# wl_phy_rxt_secure register map
Vendor: Texas Instruments
Registers are 32-bit, access per field, no defined reset value unless marked. A register's access mark holds for its fields unless they carry their own. Offsets are as the file gives them; [hi:lo] are bit positions; {n}, {i} and the like mark numbered series; <NAME> marks a mode.

## wl_phy_rxt_secure (part 2 of 2)
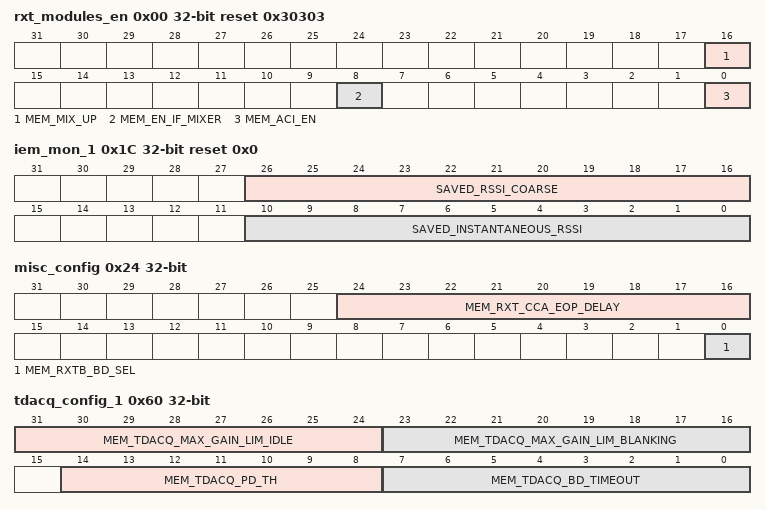
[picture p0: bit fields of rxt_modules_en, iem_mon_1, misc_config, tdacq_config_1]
0x00 rxt_modules_en reset 0x30303
  [16] MEM_MIX_UP rw, [8] MEM_EN_IF_MIXER rw, [0] MEM_ACI_EN rw
0x1C iem_mon_1 ro reset 0x0
  [26:16] SAVED_RSSI_COARSE, [10:0] SAVED_INSTANTANEOUS_RSSI
0x24 misc_config
  [24:16] MEM_RXT_CCA_EOP_DELAY rw, [0] MEM_RXTB_BD_SEL rw
0x5C tdram_config_1 reset 0x208
  [5:0] MEM_TDRAM_BD_OFFSET rw
0x60 tdacq_config_1
  [31:24] MEM_TDACQ_MAX_GAIN_LIM_IDLE rw, [23:16] MEM_TDACQ_MAX_GAIN_LIM_BLANKING rw, [14:8] MEM_TDACQ_PD_TH rw, [7:0] MEM_TDACQ_BD_TIMEOUT rw
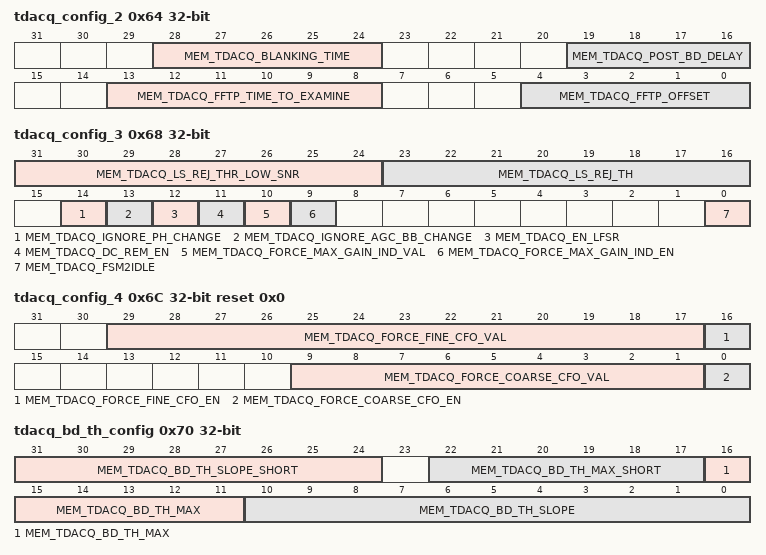
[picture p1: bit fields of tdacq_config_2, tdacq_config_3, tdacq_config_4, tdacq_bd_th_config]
0x64 tdacq_config_2
  [28:24] MEM_TDACQ_BLANKING_TIME rw, [19:16] MEM_TDACQ_POST_BD_DELAY rw, [13:8] MEM_TDACQ_FFTP_TIME_TO_EXAMINE rw, [4:0] MEM_TDACQ_FFTP_OFFSET rw
0x68 tdacq_config_3
  [31:24] MEM_TDACQ_LS_REJ_THR_LOW_SNR rw, [23:16] MEM_TDACQ_LS_REJ_TH rw, [14] MEM_TDACQ_IGNORE_PH_CHANGE rw, [13] MEM_TDACQ_IGNORE_AGC_BB_CHANGE rw, [12] MEM_TDACQ_EN_LFSR rw, [11] MEM_TDACQ_DC_REM_EN rw, [10] MEM_TDACQ_FORCE_MAX_GAIN_IND_VAL rw, [9] MEM_TDACQ_FORCE_MAX_GAIN_IND_EN rw, [0] MEM_TDACQ_FSM2IDLE rw
0x6C tdacq_config_4 reset 0x0
  [29:17] MEM_TDACQ_FORCE_FINE_CFO_VAL rw, [16] MEM_TDACQ_FORCE_FINE_CFO_EN rw, [9:1] MEM_TDACQ_FORCE_COARSE_CFO_VAL rw, [0] MEM_TDACQ_FORCE_COARSE_CFO_EN rw
0x70 tdacq_bd_th_config
  [31:24] MEM_TDACQ_BD_TH_SLOPE_SHORT rw, [22:17] MEM_TDACQ_BD_TH_MAX_SHORT rw, [16:11] MEM_TDACQ_BD_TH_MAX rw, [10:0] MEM_TDACQ_BD_TH_SLOPE rw
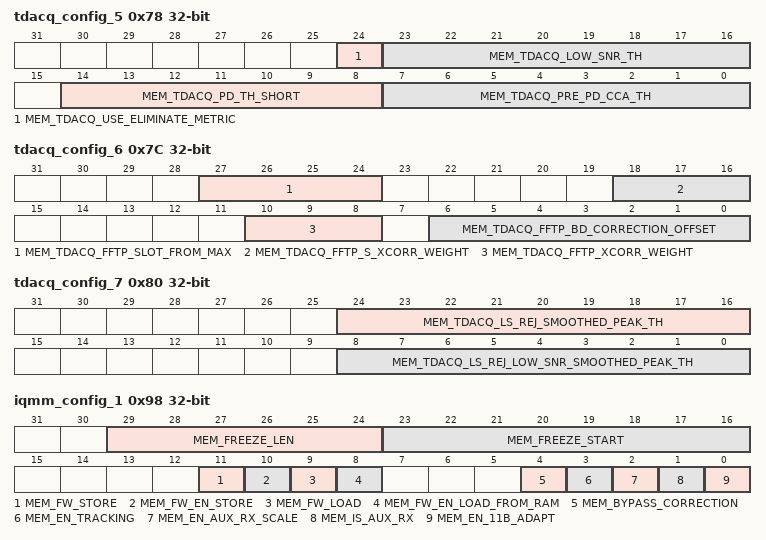
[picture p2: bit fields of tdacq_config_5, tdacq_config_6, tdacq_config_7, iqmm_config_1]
0x78 tdacq_config_5
  [24] MEM_TDACQ_USE_ELIMINATE_METRIC rw — For the short metric, weather to use the spur cancelation metric or not.
  [23:16] MEM_TDACQ_LOW_SNR_TH rw — For the LS Reject mechanism. Threshold for high/low snr. If total gain is higher than threshold, Ls Rej Low SNR thresholds are used
  [14:8] MEM_TDACQ_PD_TH_SHORT rw — Threshold for the packet detection, short metric. Raise threshold for less FA on the expense of detection probability.
  [7:0] MEM_TDACQ_PRE_PD_CCA_TH rw — Threshold for the pre PD CCA. Raise threshold for less FA on the expense of detection probability.
0x7C tdacq_config_6
  [27:24] MEM_TDACQ_FFTP_SLOT_FROM_MAX rw — The max fftp delay allowed after max values of the metrics
  [18:16] MEM_TDACQ_FFTP_S_XCORR_WEIGHT rw — For the fftp metric, multiply the difference of the SmoothedXcorr value from its max*0.625. The weight is relative to FftpXcorrWeight.
  [10:8] MEM_TDACQ_FFTP_XCORR_WEIGHT rw — For the fftp metric, multiply the difference of the Xcorr value from its max*0.625. The weight is relative to FftpSXcorrWeight.
  [6:0] MEM_TDACQ_FFTP_BD_CORRECTION_OFFSET rw — The offset we add to Equals fftp_correlation_series_start_point_in_40_MHz_clk - 2*PostBdDelay + fine tuning.
0x80 tdacq_config_7
  [24:16] MEM_TDACQ_LS_REJ_SMOOTHED_PEAK_TH rw, [8:0] MEM_TDACQ_LS_REJ_LOW_SNR_SMOOTHED_PEAK_TH rw
0x84 tdacq_config_8 reset 0x1F4FA
  [8:0] MEM_TDACQ_LS_REJ_PEAK_TH rw
0x88 tdacq_fftp_correlation_series_1 rw reset 0xAC204C53
  [31:0] MEM_TDACQ_FFTP_CORRELATION_SERIES_PH0_15
0x8C tdacq_fftp_correlation_series_2 rw reset 0x42FA156F
  [31:0] MEM_TDACQ_FFTP_CORRELATION_SERIES_PH16_31
0x90 tdacq_fftp_correlation_series_3 rw reset 0xDF141AAD
  [31:0] MEM_TDACQ_FFTP_CORRELATION_SERIES_PH32_47
0x94 tdacq_fftp_correlation_series_4 rw reset 0xC7B0EB3B
  [31:0] MEM_TDACQ_FFTP_CORRELATION_SERIES_PH48_63
0x98 iqmm_config_1
  [29:24] MEM_FREEZE_LEN rw — Freeze length in (x16) cycles
  [23:16] MEM_FREEZE_START rw — Freeze start time. The number of (x16) cycles between packet adaptation start and freeze start. 'all 1' means no freeze
  [11] MEM_FW_STORE rw
  [10] MEM_FW_EN_STORE rw
  [9] MEM_FW_LOAD rw
  [8] MEM_FW_EN_LOAD_FROM_RAM rw
  [4] MEM_BYPASS_CORRECTION rw
  [3] MEM_EN_TRACKING rw
  [2] MEM_EN_AUX_RX_SCALE rw
  [1] MEM_IS_AUX_RX rw
  [0] MEM_EN_11B_ADAPT rw
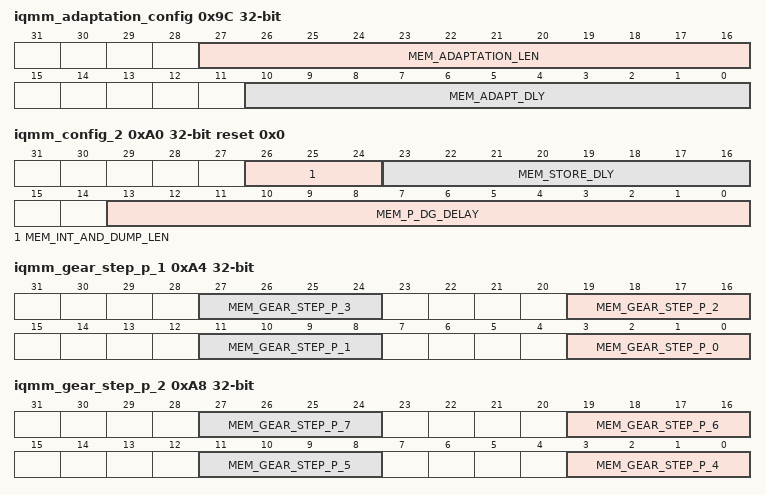
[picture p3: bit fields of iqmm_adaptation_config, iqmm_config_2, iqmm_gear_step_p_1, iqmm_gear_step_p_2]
0x9C iqmm_adaptation_config
  [27:16] MEM_ADAPTATION_LEN rw — Adaptation length of the acquisition stage (x128) cycles.
  [10:0] MEM_ADAPT_DLY rw — Delay in cycles between the adaptation start command (AgcLock or Fwstart) and the actual adaptation start.
0xA0 iqmm_config_2 reset 0x0
  [26:24] MEM_INT_AND_DUMP_LEN rw — Integrate and dump length in powers of 2. The register value represents the log2 of the length.Supports lengths of 1,16,64 and 128
  [23:16] MEM_STORE_DLY rw — Delay in cycles between the adaptation stop (end of packet or end of acquisition) and the actual P,dG and AdaptCount store to RAM
  [13:0] MEM_P_DG_DELAY rw — Delay in (x32) cycles between the Global adaptation start (where P starts) and the dG adaptation start.
0xA4 iqmm_gear_step_p_1
  [8n+3:8n] MEM_GEAR_STEP_P_{n} rw (n=0..3) — P step size function values - in number of shift left operations. Bus span is 0 to 15, it represents gears 2 to 17
0xA8 iqmm_gear_step_p_2
  [8n-29:8n-32] MEM_GEAR_STEP_P_{n} rw (n=4..7) — P step size function values - in number of shift left operations. Bus span is 0 to 15, it represents gears 2 to 17
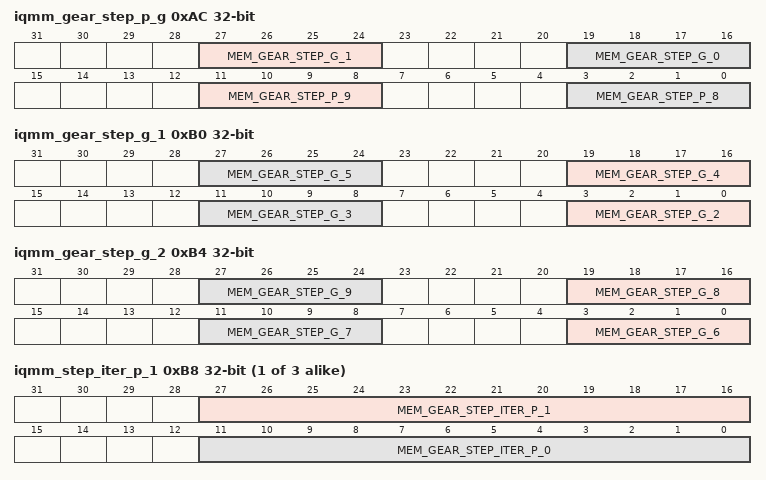
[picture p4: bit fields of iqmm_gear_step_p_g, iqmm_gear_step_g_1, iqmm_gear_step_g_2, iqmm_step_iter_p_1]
0xAC iqmm_gear_step_p_g
  [27:24] MEM_GEAR_STEP_G_1 rw — dG step size function values - in number of shift left operations. Bus span is 0 to 15, it represents gears 2 to 17
  [19:16] MEM_GEAR_STEP_G_0 rw — dG step size function values - in number of shift left operations. Bus span is 0 to 15, it represents gears 2 to 17
  [11:8] MEM_GEAR_STEP_P_9 rw — P step size function values - in number of shift left operations. Bus span is 0 to 15, it represents gears 2 to 17
  [3:0] MEM_GEAR_STEP_P_8 rw — P step size function values - in number of shift left operations. Bus span is 0 to 15, it represents gears 2 to 17
0xB0 iqmm_gear_step_g_1
  [8n-13:8n-16] MEM_GEAR_STEP_G_{n} rw (n=2..5) — dG step size function values - in number of shift left operations. Bus span is 0 to 15, it represents gears 2 to 17
0xB4 iqmm_gear_step_g_2
  [8n-45:8n-48] MEM_GEAR_STEP_G_{n} rw (n=6..9) — dG step size function values - in number of shift left operations. Bus span is 0 to 15, it represents gears 2 to 17
{0xB4+4i} iqmm_step_iter_p_{i} (i=1..3)
  [27:16] MEM_GEAR_STEP_ITER_P_{2i-1} rw — P step size function time stamp values - in resolution of (x128) cycles.
  [11:0] MEM_GEAR_STEP_ITER_P_{2i-2} rw — P step size function time stamp values - in resolution of (x128) cycles.
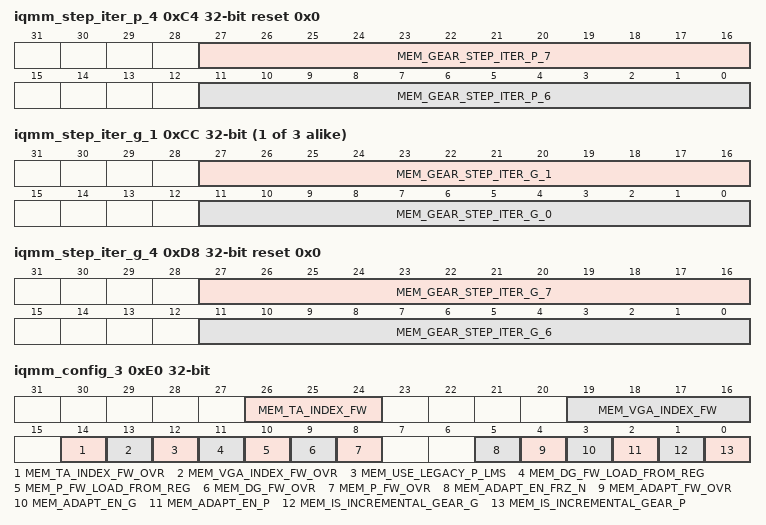
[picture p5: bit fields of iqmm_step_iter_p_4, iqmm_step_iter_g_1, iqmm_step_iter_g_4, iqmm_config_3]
0xC4 iqmm_step_iter_p_4 reset 0x0
  [27:16] MEM_GEAR_STEP_ITER_P_7 rw — P step size function time stamp values - in resolution of (x128) cycles.
  [11:0] MEM_GEAR_STEP_ITER_P_6 rw — P step size function time stamp values - in resolution of (x128) cycles.
0xC8 iqmm_step_iter_p_5 reset 0x0
  [11:0] MEM_GEAR_STEP_ITER_P_8 rw — P step size function time stamp values - in resolution of (x128) cycles.
{0xC8+4i} iqmm_step_iter_g_{i} (i=1..3)
  [27:16] MEM_GEAR_STEP_ITER_G_{2i-1} rw — dG step size function time stamp values - in resolution of (x128) cycles.
  [11:0] MEM_GEAR_STEP_ITER_G_{2i-2} rw — dG step size function time stamp values - in resolution of (x128) cycles.
0xD8 iqmm_step_iter_g_4 reset 0x0
  [27:16] MEM_GEAR_STEP_ITER_G_7 rw — dG step size function time stamp values - in resolution of (x128) cycles.
  [11:0] MEM_GEAR_STEP_ITER_G_6 rw — dG step size function time stamp values - in resolution of (x128) cycles.
0xDC iqmm_step_iter_g_5 reset 0x0
  [11:0] MEM_GEAR_STEP_ITER_G_8 rw — dG step size function time stamp values - in resolution of (x128) cycles.
0xE0 iqmm_config_3
  [26:24] MEM_TA_INDEX_FW rw — Ta Index value from FW [0..4]
  [19:16] MEM_VGA_INDEX_FW rw — Vga Index value from FW [0..8]
  [14] MEM_TA_INDEX_FW_OVR rw
  [13] MEM_VGA_INDEX_FW_OVR rw
  [12] MEM_USE_LEGACY_P_LMS rw
  [11] MEM_DG_FW_LOAD_FROM_REG rw
  [10] MEM_P_FW_LOAD_FROM_REG rw
  [9] MEM_DG_FW_OVR rw
  [8] MEM_P_FW_OVR rw
  [5] MEM_ADAPT_EN_FRZ_N rw
  [4] MEM_ADAPT_FW_OVR rw
  [3] MEM_ADAPT_EN_G rw
  [2] MEM_ADAPT_EN_P rw
  [1] MEM_IS_INCREMENTAL_GEAR_G rw
  [0] MEM_IS_INCREMENTAL_GEAR_P rw
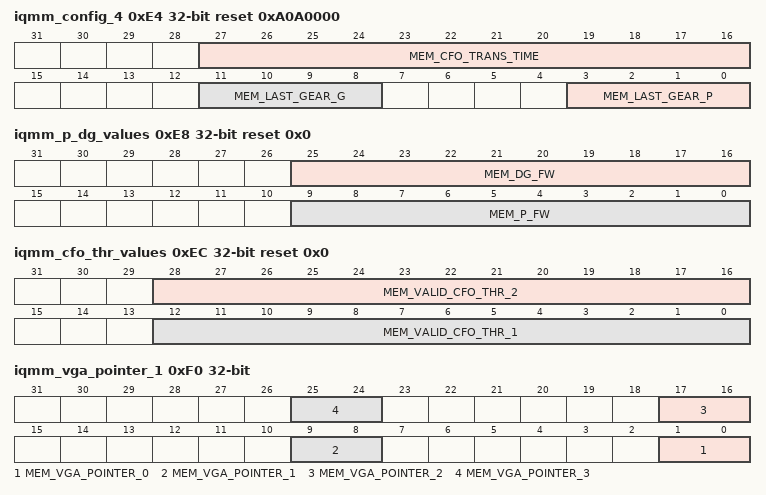
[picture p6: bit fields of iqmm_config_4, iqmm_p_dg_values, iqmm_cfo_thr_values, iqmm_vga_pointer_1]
0xE4 iqmm_config_4 reset 0xA0A0000 (reset mask 0xFFF0000)
  [27:16] MEM_CFO_TRANS_TIME rw — The time in x128 samples to switch between ValidCfoThr1 and ValidCfoThr2
  [11:8] MEM_LAST_GEAR_G rw — Last G Gear limit
  [3:0] MEM_LAST_GEAR_P rw — Last P Gear limit
0xE8 iqmm_p_dg_values reset 0x0
  [25:16] MEM_DG_FW rw — dG value from FW used for FW override or to load into the LMS loop
  [9:0] MEM_P_FW rw — P value from FW used for FW override or to load into the LMS loop
0xEC iqmm_cfo_thr_values reset 0x0
  [28:16] MEM_VALID_CFO_THR_2 rw — Second CFO Threshold to validate the packet adaptation cycle. If the CFO is lower than the threshold the packet adaptation result will not be written to the RAM This threshold is used when AdaptCount > CfoThrTransTime.
  [12:0] MEM_VALID_CFO_THR_1 rw — First CFO Threshold to validate the packet adaptation cycle. If the CFO is lower than the threshold the packet adaptation result will not be written to the RAM. This threshold is used when AdaptCount <= CfoThrTransTime
0xF0 iqmm_vga_pointer_1
  [8n+1:8n] MEM_VGA_POINTER_{n} rw (n=0..3)
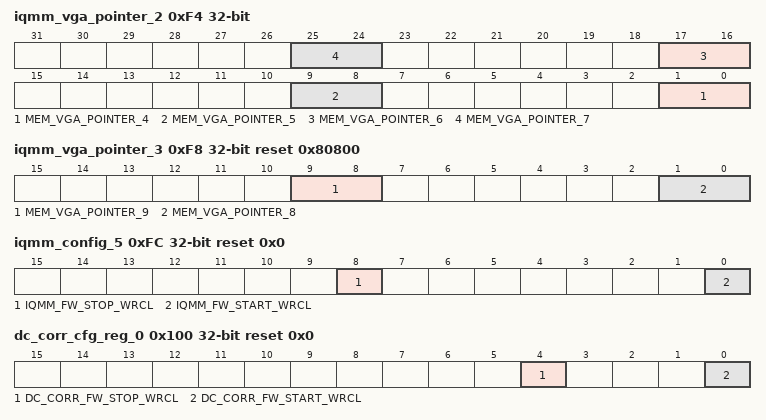
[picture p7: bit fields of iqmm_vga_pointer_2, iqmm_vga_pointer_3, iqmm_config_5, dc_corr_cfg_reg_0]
0xF4 iqmm_vga_pointer_2
  [8n-31:8n-32] MEM_VGA_POINTER_{n} rw (n=4..7)
0xF8 iqmm_vga_pointer_3 reset 0x80800 (reset mask 0xFFFFFC00)
  [9:8] MEM_VGA_POINTER_9 rw, [1:0] MEM_VGA_POINTER_8 rw
0xFC iqmm_config_5 reset 0x0
  [8] IQMM_FW_STOP_WRCL wo, [0] IQMM_FW_START_WRCL wo
0x100 dc_corr_cfg_reg_0 reset 0x0 — FW Overwrite configuration register
  [4] DC_CORR_FW_STOP_WRCL wo — Stop the DC correction - triggered from FW. Self Clear <1.0u>
  [0] DC_CORR_FW_START_WRCL wo — Start new DC correction - triggered from FW. Self Clear <1.0u>
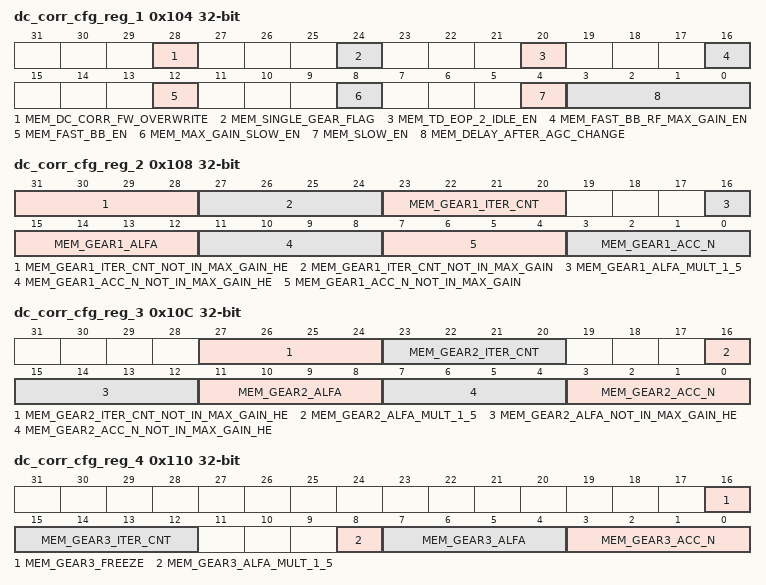
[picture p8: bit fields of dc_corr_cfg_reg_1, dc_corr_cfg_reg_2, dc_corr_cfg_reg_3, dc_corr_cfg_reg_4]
0x104 dc_corr_cfg_reg_1 — Enable configuration register
  [28] MEM_DC_CORR_FW_OVERWRITE rw — If set, only the FW controls start/stop and not inner signals such as Abort/EOP/StartTd <1.0u>
  [24] MEM_SINGLE_GEAR_FLAG rw — If set, only the first gear is used <1.0u>
  [20] MEM_TD_EOP_2_IDLE_EN rw — If enabled, EOP packet pulse resets the DC correction into idle. <1.0u>
  [16] MEM_FAST_BB_RF_MAX_GAIN_EN rw — If set, BB(VGA) change will cause scaling of the DC correction value (according to the VGA change) without reset of the DC module only when RF is in max gain (LNA+TA). <1.0u>
  [12] MEM_FAST_BB_EN rw — If set, BB(VGA) change will cause scaling of the DC correction value (according to the VGA change) without reset of the DC module (DC is assumed constant during BB change). <1.0u>
  [8] MEM_MAX_GAIN_SLOW_EN rw — When enabled, enables switching from Gear 3 STATE into Slow1 STATE only if AGC is in max gain. <1.0u>
  [4] MEM_SLOW_EN rw — When enabled always switch from Gear 3 STATE into Slow1 STATE <1.0u>
  [3:0] MEM_DELAY_AFTER_AGC_CHANGE rw — Delay value after agc change (RfChange|BBChange) <4.0u>
0x108 dc_corr_cfg_reg_2 — Gear 1 configuation register
  [31:28] MEM_GEAR1_ITER_CNT_NOT_IN_MAX_GAIN_HE rw — Number of clocks to stay at Gear1. This register is used after AGC change in the middle of the He-STF to prevent DC change after possible long ?Gear1AccN?(as is the default value) which might interfere with the He-LTF estimation. We want to ensure Gear1AccNNotInMaxGainHe is used only once(equals Gear1AccNNotInMaxGainHe) <4.0u>
  [27:24] MEM_GEAR1_ITER_CNT_NOT_IN_MAX_GAIN rw — Number of clocks to stay at Gear1. Number of clocks to stay at Gear1. value is This register is used after AGC change in the middle of the legacy preamble to prevent first DC change after possible long ?Gear1AccN?(as is the default value) which might interfere with the placement algorithm. We allow different register for that mode. We want to ensure Gear1AccNNotInMaxGain is used only once(equals Gear1AccNNotInMaxGain) <4.0u>
  [23:20] MEM_GEAR1_ITER_CNT rw — Number of clocks to stay at Gear1. <4.0u>
  [16] MEM_GEAR1_ALFA_MULT_1_5 rw — 1.5 multiplier enable for Alfa of Gear 1 <1.0u>
  [15:12] MEM_GEAR1_ALFA rw — Alfa value for Gear1. <4.0u>
  [11:8] MEM_GEAR1_ACC_N_NOT_IN_MAX_GAIN_HE rw — Accumulator duration (40Mhz cycles) for Gear1 when not in max gain. This register is used after AGC change in the middle of the He-STF to prevent DC change after possible long ?Gear1AccN?(as is the default value) which might interfere with the He-LTF estimation. <4.0u>
  [7:4] MEM_GEAR1_ACC_N_NOT_IN_MAX_GAIN rw — Accumulator duration (40Mhz cycles) for Gear1 when not in max gain. This register is used after AGC change in the middle of the legacy preamble to prevent first DC change after possible long ?Gear1AccN?(as is the default value) which might interfere with the placement algorithm. We allow different register for that mode. <4.0u>
  [3:0] MEM_GEAR1_ACC_N rw — Accumulator duration (40Mhz cycles) for Gear1. <4.0u>
0x10C dc_corr_cfg_reg_3 — Gear 2 configuration register
  [27:24] MEM_GEAR2_ITER_CNT_NOT_IN_MAX_GAIN_HE rw — Number of clocks to stay at Gear2. See explanation in Gear2AccnNotInMaxGainHe <4.0u>
  [23:20] MEM_GEAR2_ITER_CNT rw — Number of clocks to stay at Gear2. <4.0u>
  [16] MEM_GEAR2_ALFA_MULT_1_5 rw — 1.5 multiplier enable for Alfa of Gear 2 <1.0u>
  [15:12] MEM_GEAR2_ALFA_NOT_IN_MAX_GAIN_HE rw — Alfa value for Gear2. See explanation in Gear2AccnNotInMaxGainHe <4.0u>
  [11:8] MEM_GEAR2_ALFA rw — Alfa value for Gear2. <4.0u>
  [7:4] MEM_GEAR2_ACC_N_NOT_IN_MAX_GAIN_HE rw — Accumulator duration (40Mhz cycles) for Gear2. Accumulator duration (40Mhz cycles) for Gear2. Value is This register is used after AGC change in the middle of the He-STF to prevent DC change after possible long ?Gear1AccN?(as is the default value) which might interfere with the He-LTF estimation. After first averaging with duration 1.6usec (Gear1AccNNotInMaxGainHe) we want 0.8 usec more averaging with gear2. <4.0u>
  [3:0] MEM_GEAR2_ACC_N rw — Accumulator duration (40Mhz cycles) for Gear2. <4.0u>
0x110 dc_corr_cfg_reg_4 — Gear 3 configuration register
  [16] MEM_GEAR3_FREEZE rw — Freeze adaptation for gear3 <1.0u>
  [15:12] MEM_GEAR3_ITER_CNT rw — Number of clocks to stay at Gear3. <4.0u>
  [8] MEM_GEAR3_ALFA_MULT_1_5 rw — 1.5 multiplier enable for Alfa of Gear 3 <1.0u>
  [7:4] MEM_GEAR3_ALFA rw — Alfa value for Gear3. <4.0u>
  [3:0] MEM_GEAR3_ACC_N rw — Accumulator duration (40Mhz cycles) for Gear3. <4.0>
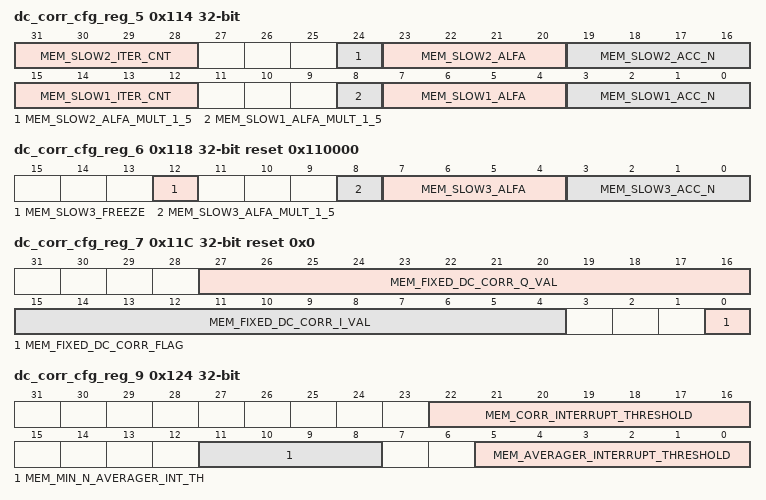
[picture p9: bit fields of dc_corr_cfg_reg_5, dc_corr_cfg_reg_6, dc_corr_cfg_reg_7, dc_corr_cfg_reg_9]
0x114 dc_corr_cfg_reg_5 — Slow 1 and Slow 2 configuration register
  [31:28] MEM_SLOW2_ITER_CNT rw — Number of clocks to stay at Slow2. <4.0u>
  [24] MEM_SLOW2_ALFA_MULT_1_5 rw — 1.5 multiplier enable for Alfa of Slow 2 <1.0u>
  [23:20] MEM_SLOW2_ALFA rw — Alfa value for Slow2. <4.0u>
  [19:16] MEM_SLOW2_ACC_N rw — Accumulator duration (40Mhz cycles) for Slow2. <4.0u>
  [15:12] MEM_SLOW1_ITER_CNT rw — Number of clocks to stay at Slow1. <4.0u>
  [8] MEM_SLOW1_ALFA_MULT_1_5 rw — 1.5 multiplier enable for Alfa of Slow 1 <1.0u>
  [7:4] MEM_SLOW1_ALFA rw — Alfa value for Slow1. <4.0u>
  [3:0] MEM_SLOW1_ACC_N rw — Accumulator duration (40Mhz cycles) for Slow1. <4.0u>
0x118 dc_corr_cfg_reg_6 reset 0x110000 (reset mask 0xFFFFE000) — Slow 3 configuration register
  [12] MEM_SLOW3_FREEZE rw — Freeze adaptation for Slow3 <1.0u>
  [8] MEM_SLOW3_ALFA_MULT_1_5 rw — 1.5 multiplier enable for Alfa of Slow 3 <4.0u>
  [7:4] MEM_SLOW3_ALFA rw — Alfa value for Slow3. <4.0u>
  [3:0] MEM_SLOW3_ACC_N rw — Accumulator duration (40Mhz cycles) for Slow3. <4.0u>
0x11C dc_corr_cfg_reg_7 reset 0x0 — Fixed DC correction configuration register
  [27:16] MEM_FIXED_DC_CORR_Q_VAL rw — Imaginary part of external forced DC correction <1.11s>
  [15:4] MEM_FIXED_DC_CORR_I_VAL rw — Real part of external forced DC correction <1.11s>
  [0] MEM_FIXED_DC_CORR_FLAG rw — If set, overwrite DC correction by FixedDcCorrectionVal_XX <1.0u>
0x124 dc_corr_cfg_reg_9 — Interrrupt thresholds configuration register
  [22:16] MEM_CORR_INTERRUPT_THRESHOLD rw — If the amplitude (real or imag) of the Correction exceeds register CorrInterruptThreshold, BigCorrInt is set high. <0.7u>
  [11:8] MEM_MIN_N_AVERAGER_INT_TH rw — If the current gear?s AccN equals/greater than MinNAveragerIntTh then CorrInterrupt is enabled. <0.4u>
  [5:0] MEM_AVERAGER_INTERRUPT_THRESHOLD rw — If the amplitude (real or imag) of the averager exceeds register AvergarerInterruptThreshold, BigAveragerInt is set high. <0.6u>
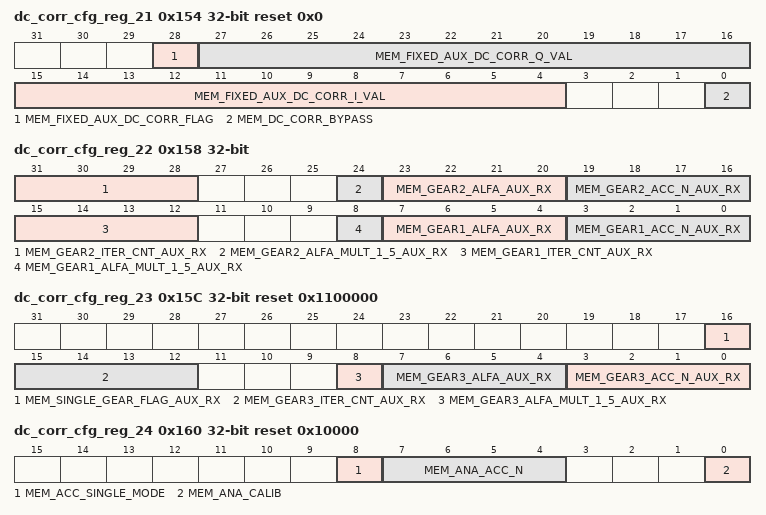
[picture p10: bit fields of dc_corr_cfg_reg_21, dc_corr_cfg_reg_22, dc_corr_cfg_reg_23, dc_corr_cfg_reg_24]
0x154 dc_corr_cfg_reg_21 reset 0x0 — DC Correction bypass configuration register
  [28] MEM_FIXED_AUX_DC_CORR_FLAG rw — If set, overwrite DC correction by FixedAuxRxDcCorrectionVal_XX when in aux rx mode (Tx calibration mode). <1.0u>
  [27:16] MEM_FIXED_AUX_DC_CORR_Q_VAL rw — Imaginary part of external forced DC correction when in aux rx (Tx calibration mode). <1.11s>
  [15:4] MEM_FIXED_AUX_DC_CORR_I_VAL rw — Real part of external forced DC correction when in aux rx mode (Tx calibration mode). <1.11s>
  [0] MEM_DC_CORR_BYPASS rw — If set, the DC correction is bypassed. <1.0u>
0x158 dc_corr_cfg_reg_22 — Gear 1 and Gear 2 Aux RX configuration register
  [31:28] MEM_GEAR2_ITER_CNT_AUX_RX rw — Number of clocks to stay at Gear2. <4.0u>
  [24] MEM_GEAR2_ALFA_MULT_1_5_AUX_RX rw — 1.5 multiplier enable for Alfa of Gear 2 <1.0u>
  [23:20] MEM_GEAR2_ALFA_AUX_RX rw — Alfa value for Gear2. <4.0u>
  [19:16] MEM_GEAR2_ACC_N_AUX_RX rw — Accumulator duration (40Mhz cycles) for Gear2. <4.0u>
  [15:12] MEM_GEAR1_ITER_CNT_AUX_RX rw — Number of clocks to stay at Gear1. <4.0u>
  [8] MEM_GEAR1_ALFA_MULT_1_5_AUX_RX rw — 1.5 multiplier enable for Alfa of Gear 1. <4.0u>
  [7:4] MEM_GEAR1_ALFA_AUX_RX rw — Alfa value for Gear1. <4.0u>
  [3:0] MEM_GEAR1_ACC_N_AUX_RX rw — Accumulator duration (40Mhz cycles) for Gear1. <4.0u>
0x15C dc_corr_cfg_reg_23 reset 0x1100000 (reset mask 0xFFFE0000) — Gear 3 and Signle gear Aux RX configuration register
  [16] MEM_SINGLE_GEAR_FLAG_AUX_RX rw — If set, only the first gear is used when in IsAuxRxMode <1.0u>
  [15:12] MEM_GEAR3_ITER_CNT_AUX_RX rw — Number of clocks to stay at Gear3. <4.0u>
  [8] MEM_GEAR3_ALFA_MULT_1_5_AUX_RX rw — 1.5 multiplier enable for Alfa of Gear 3 <1.0u>
  [7:4] MEM_GEAR3_ALFA_AUX_RX rw — Alfa value for Gear3. <4.0u>
  [3:0] MEM_GEAR3_ACC_N_AUX_RX rw — Accumulator duration (40Mhz cycles) for Gear3. <4.0>
0x160 dc_corr_cfg_reg_24 reset 0x10000 (reset mask 0xFFFFFE00) — Analog calibration configuration register
  [8] MEM_ACC_SINGLE_MODE rw — If set, the accumulator accumulates and dumps only one time (into Averager status register) after SingleMode is set high. The averaging duration is based on its current AccN value. In order to get new value for Averager status register, SingleMode register has to be reset and set. Important note: This register doesn?t change any other module functionality (The gears are progressing/DC correction is active, etc.). <1.0u>
  [7:4] MEM_ANA_ACC_N rw — Accumulator duration (40Mhz cycles) irrespective of the gear when AnalogCalib is set high. <4.0u>
  [0] MEM_ANA_CALIB rw — If set, the accumulator accumulates and dumps 2^ AccNAnalogCalib samples irrespective of the gear. Important note: This register doesn?t change any other module functionality (The gears are progressing/DC correction is active, etc.). <1.0u>
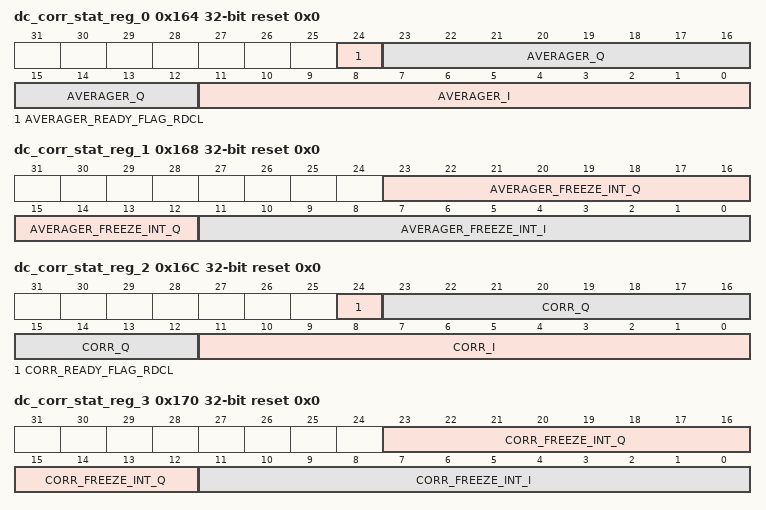
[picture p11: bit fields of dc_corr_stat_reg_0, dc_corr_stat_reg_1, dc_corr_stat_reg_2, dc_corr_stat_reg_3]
0x164 dc_corr_stat_reg_0 ro reset 0x0 — Averager status register
  [24] AVERAGER_READY_FLAG_RDCL — Set to high every update of Averager value. <1.0u>
  [23:12] AVERAGER_Q — The result of averaging imag branch GearXXAccN/ AccNAnalogCalib samples. This result is updated only once after ?SingleMode? register is set high. <1.11s>
  [11:0] AVERAGER_I — The result of averaging real branch GearXXAccN/ AccNAnalogCalib samples. This result is updated only once after ?SingleMode? register is set high. <1.11s>
0x168 dc_corr_stat_reg_1 ro reset 0x0 — Averager freeze status register
  [23:12] AVERAGER_FREEZE_INT_Q — The value of the imag branch Averager when BigAveragerInt set high.This value is max hold and FW should reset it during read.Each I/Q is freezed separately. <1.11s>
  [11:0] AVERAGER_FREEZE_INT_I — The value of the real branch Averager when BigAveragerInt set high.This value is max hold and FW should reset it during read.Each I/Q is freezed separately. <1.11s>
0x16C dc_corr_stat_reg_2 ro reset 0x0 — Correction status register
  [24] CORR_READY_FLAG_RDCL — Set to high every update of Corr value.
  [23:12] CORR_Q — DC correction imag branch value to be applied to input. <1.11s>
  [11:0] CORR_I — DC correction real branch value to be applied to input. <1.11s>
0x170 dc_corr_stat_reg_3 ro reset 0x0 — Correction freeze status register
  [23:12] CORR_FREEZE_INT_Q — The value of the imag branch Corr when BigCorrInt set high.This value is max hold and FW should reset it during read. Each I/Q is freezed separately. <1.11s>
  [11:0] CORR_FREEZE_INT_I — The value of the real branch Corr when BigCorrInt set high.This value is max hold and FW should reset it during read. Each I/Q is freezed separately. <1.11s>
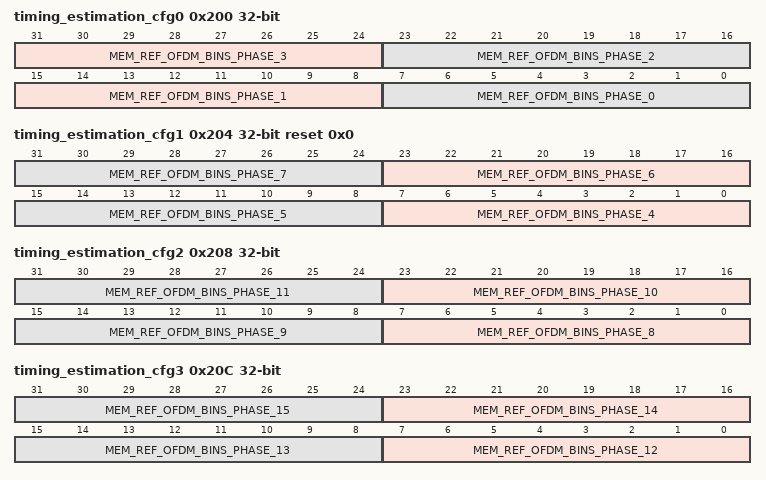
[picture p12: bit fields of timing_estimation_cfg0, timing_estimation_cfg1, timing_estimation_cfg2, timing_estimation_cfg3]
0x200 timing_estimation_cfg0 rw
  [31:24] MEM_REF_OFDM_BINS_PHASE_3 — Expected normalized phase which are matched to selected bins phase
  [23:16] MEM_REF_OFDM_BINS_PHASE_2 — Expected normalized phase which are matched to selected bins phase
  [15:8] MEM_REF_OFDM_BINS_PHASE_1 — Expected normalized phase which are matched to selected bins phase.
  [7:0] MEM_REF_OFDM_BINS_PHASE_0 — Expected normalized phase which are matched to selected bins phase.
0x204 timing_estimation_cfg1 rw reset 0x0
  [8n-25:8n-32] MEM_REF_OFDM_BINS_PHASE_{n} (n=4..7) — Expected normalized phase which are matched to selected bins phase
0x208 timing_estimation_cfg2 rw
  [8n-57:8n-64] MEM_REF_OFDM_BINS_PHASE_{n} (n=8..11) — Expected normalized phase which are matched to selected bins phase
0x20C timing_estimation_cfg3 rw
  [8n-89:8n-96] MEM_REF_OFDM_BINS_PHASE_{n} (n=12..15) — Expected normalized phase which are matched to selected bins phase
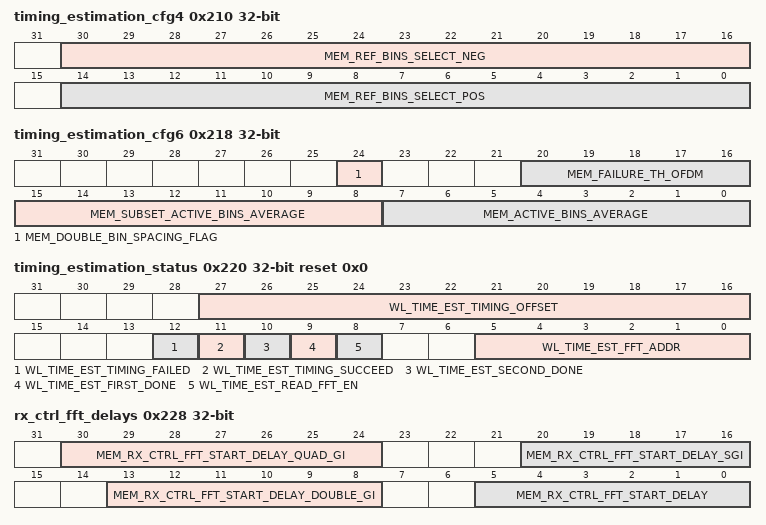
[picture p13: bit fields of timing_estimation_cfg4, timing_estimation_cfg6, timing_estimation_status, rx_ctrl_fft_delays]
0x210 timing_estimation_cfg4
  [30:16] MEM_REF_BINS_SELECT_NEG rw — Selection of active bins.
  [14:0] MEM_REF_BINS_SELECT_POS rw — Selection of active bins.
0x218 timing_estimation_cfg6
  [24] MEM_DOUBLE_BIN_SPACING_FLAG rw — If set, the active bins used for estimation will be taken from twice bin index as defined in Ref_ofdm_bins_select_XX.
  [20:16] MEM_FAILURE_TH_OFDM rw — This is the accumulated distance threshold between true and estimated phase. If accumulated distance exceeds Failure_th, then estimation failed.
  [15:8] MEM_SUBSET_ACTIVE_BINS_AVERAGE rw
  [7:0] MEM_ACTIVE_BINS_AVERAGE rw
0x21C timing_estimation_cfg7 reset 0x28341
  [8:0] MEM_INV_SCALING rw
0x220 timing_estimation_status ro reset 0x0
  [27:16] WL_TIME_EST_TIMING_OFFSET, [12] WL_TIME_EST_TIMING_FAILED, [11] WL_TIME_EST_TIMING_SUCCEED, [10] WL_TIME_EST_SECOND_DONE, [9] WL_TIME_EST_FIRST_DONE, [8] WL_TIME_EST_READ_FFT_EN, [5:0] WL_TIME_EST_FFT_ADDR
0x224 timing_estimation_status_2 ro reset 0x0
  [7:0] WL_TIME_EST_COMMON_PHASE
0x228 rx_ctrl_fft_delays
  [30:24] MEM_RX_CTRL_FFT_START_DELAY_QUAD_GI rw — Configurable delay to align the FftStart of the HE-LTF when GI=3.2usec according to the new Fft placement value.
  [20:16] MEM_RX_CTRL_FFT_START_DELAY_SGI rw — Configurable delay to align the FftStart of the HT/VHT-LTF in an SGI packet according to the new Fft placement value. FftStartDelaySgi = 16 + FftpSgi ? Fftp
  [13:8] MEM_RX_CTRL_FFT_START_DELAY_DOUBLE_GI rw — Configurable delay to align the FftStart of the HE-LTF when GI=1.6usec according to the new Fft placement value.
  [5:0] MEM_RX_CTRL_FFT_START_DELAY rw — Configurable delay for the first FftStart. Used as part of the total delay from BD to the first FftStart.
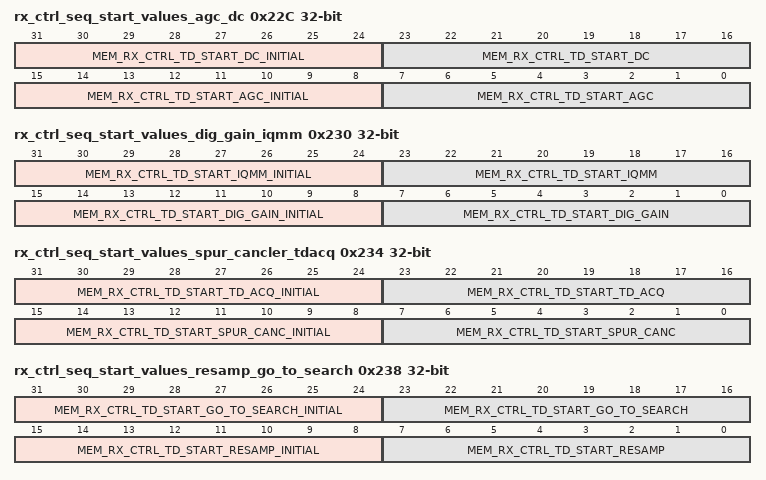
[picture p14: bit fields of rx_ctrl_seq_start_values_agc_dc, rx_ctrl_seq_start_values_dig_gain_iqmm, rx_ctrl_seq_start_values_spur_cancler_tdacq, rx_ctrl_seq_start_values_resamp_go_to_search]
0x22C rx_ctrl_seq_start_values_agc_dc rw
  [31:24] MEM_RX_CTRL_TD_START_DC_INITIAL — Dc cancellation start time for 1st packet sequence
  [23:16] MEM_RX_CTRL_TD_START_DC — Dc cancellation start time for 2nd sequence
  [15:8] MEM_RX_CTRL_TD_START_AGC_INITIAL — Agc start time for 1st packet sequence
  [7:0] MEM_RX_CTRL_TD_START_AGC — Agc start time for 2nd sequence
0x230 rx_ctrl_seq_start_values_dig_gain_iqmm rw
  [31:24] MEM_RX_CTRL_TD_START_IQMM_INITIAL — Iqmm start time for 1st packet sequence
  [23:16] MEM_RX_CTRL_TD_START_IQMM — Iqmm start time for 2nd sequence
  [15:8] MEM_RX_CTRL_TD_START_DIG_GAIN_INITIAL — Dig gain start time for 1st packet sequence
  [7:0] MEM_RX_CTRL_TD_START_DIG_GAIN — Dig gain start time for 2nd sequence
0x234 rx_ctrl_seq_start_values_spur_cancler_tdacq rw
  [31:24] MEM_RX_CTRL_TD_START_TD_ACQ_INITIAL — td_acq start time for 1st packet
  [23:16] MEM_RX_CTRL_TD_START_TD_ACQ — td_acq start time for 2nd sequence
  [15:8] MEM_RX_CTRL_TD_START_SPUR_CANC_INITIAL — spur canceler start time for 1st packet sequence
  [7:0] MEM_RX_CTRL_TD_START_SPUR_CANC — spur canceler start time for 2nd sequence
0x238 rx_ctrl_seq_start_values_resamp_go_to_search rw
  [31:24] MEM_RX_CTRL_TD_START_GO_TO_SEARCH_INITIAL — 2nd packet sequence done time
  [23:16] MEM_RX_CTRL_TD_START_GO_TO_SEARCH — 1st packet sequence done time
  [15:8] MEM_RX_CTRL_TD_START_RESAMP_INITIAL — Reset resampler time for 1st packet sequence
  [7:0] MEM_RX_CTRL_TD_START_RESAMP — Reset resampler time for 2nd sequence
0x23C rx_ctrl_seq_start_values_cca_rx_meters rw
  [31:24] MEM_RX_CTRL_TD_START_RX_METERS_INITIAL — Rx Meters start time for 1st packet sequence
  [23:16] MEM_RX_CTRL_TD_START_RX_METERS — Rx Meters start time for 2nd packet sequence
  [15:8] MEM_RX_CTRL_TD_START_CCA_INITIAL — CCA start time for 1st packet sequence
  [7:0] MEM_RX_CTRL_TD_START_CCA — CCA start time for 2nd packet sequence
0x240 rx_ctrl_delays
  [28:24] MEM_RX_CTRL_THIRD_B2B_DELAY rw — Additional delay to 3rd B2B. Sets the transition time from Unknow1 state to Unknown2 state. This is additional delay to a 3.25usec timer
  [23:16] MEM_RX_CTRL_TD_EOP_DELAY_OFDM rw — Alignment of the TdEop output. The TdEop indicates the end of an OFDM packet at the TdRam input. This register represents the number of samples before the timer of the RxSM LastSymbol state expires. TdEop time = StateCounter - TdEopDelayOfdm
  [15:8] MEM_RX_CTRL_TD_EOP_DELAY_11B rw — Delay (samples) from 11bDone to TdEop of a 11B packet
  [5:0] MEM_RX_CTRL_CP_IN_RESAMP_DELAY rw — Configurable delay for the CpInResampler pulse. Sets the indication distance (samples) from the Fftp sample write time to the TdRam.
0x244 rx_ctrl_seq_cfg reset 0x3FF (reset mask 0x3FF)
  [24] MEM_RX_CTRL_TD_SEQ_SELECT rw — Select sequence (when TdSeqOvr is true) : 0 - Initial sequence ,1 - 2nd sequence
  [16] MEM_RX_CTRL_TD_SEQ_OVR rw — Override auto sequence selection
  [9:0] MEM_RX_CTRL_SHORT_START_VALID rw — Selects the start pulses in short start mode (used after RxStomp). Each bit represents an output: 0 - Agc 1 - ResetResampler 2 - StartDc 3 - StartDigGain 4 - StartIqmm 5 - SpurCanc 6 - TdAcq 7 - GoToSearch 8 - CCA 9 - Rx Meters
0x248 rx_ctrl_phy_b
  [27:24] MEM_RX_CTRL_PHYB_STATE_FOR_INTERRUPT rw
  [17] MEM_RX_CTRL_PHYB_SELECT_TRIGGER rw — Trigger select for OFDM/11b detection. 0 - PD/11bPD for OFDM/11b trigger 1 - BD/11bBD for OFDM/11b trigger
  [15:8] MEM_RX_CTRL_PHYB_PEND_B_TIMER rw — Delay (samples) from 11bTrigger to B_Only state
  [7:0] MEM_RX_CTRL_PHYB_START_B_TIMER rw — Delay (samples) from Start11b to Wait_B_or_N state
0x24C rx_ctrl_config reset 0x800000 (reset mask 0xFFFFF000)
  [11] MEM_RX_CTRL_SM_RETURN_IDLE_WITH_TD_EOP rw — Rx Sm return to IDLE at Td_Eop pulse
  [10] MEM_RX_CTRL_FD_RESET_IN_BD_OR_FFTP rw — 0 reset FD at Fftp done event 1 reset FD at BD event
  [9] MEM_RX_CTRL_USE_TD_SEQ_ON_RX_STOMP rw — Use the TdSequencer sequence instead of the short start option after RxStomp
  [8] MEM_RX_CTRL_USE_SHORT_START_ON_RX_START rw — Use the short start option in the TdSequencer instead of the regular sequence on RxStart command. Start pulses will be according to the ShortStartVec register
  [1:0] MEM_RX_CTRL_RXT_MODE rw — 0 - no 11b no OFDM 1 - OFDM no 11b 2 - 11b no OFDM 3 - OFDM and 11b
0x250 rx_ctrl_suspend_cfg_1
  [24:16] MEM_RX_CTRL_TD_ACQ_SEQ_AFTER_HE rw
  [14:8] MEM_RX_CTRL_N4_USEC_SYMB_THR_FOR_FULL_SUSPEND rw — Number of 4[uSec] symbols threshold for validating analog chain and PLL turn off in RxSuspend mode. It represents the threshold for number of symbols left to end of packet.
  [5:0] MEM_RX_CTRL_N4_USEC_SYMB_THR_FOR_ANA_SUSPEND rw — Number of 4[uSec] symbols threshold for validating analog chain turn off in RxSuspend mode. It represents the threshold for number of symbols left to end of packet.
0x254 rx_ctrl_suspend_cfg_2
  [27] MEM_RX_CTRL_FW_SUSPEND_NO_STOMP_EMULATION rw — 1 - FW might force suspend (with suspend_trigger_emulation). 0 - No FW suspend is possible
  [26] MEM_RX_CTRL_REG_EN_PLL_SUSPEND rw — Enable to the SUSPEND_FD_ANA_PLL mode. In this mode we close the pll, the analog and the FD.#br#
  [25] MEM_RX_CTRL_REG_EN_ANA_SUSPEND rw — Enable to the SUSPEND_FD_ANA mode. In this mode we close the analog and the FD.#br#
  [24] MEM_RX_CTRL_REG_EN_FD_SUSPEND rw — Enable the basic operation of the suspend feature. Closing the FD only.
  [19:16] MEM_RX_CTRL_USEC_TO_SUSPEND_END_FD rw — Number of uSec to suspend end threshold. Represents a time threshold (in micro seconds) from the end of packet when a SuspendEnd interrupt is issued when suspendType==SUSPEND_FD
  [14:8] MEM_RX_CTRL_USEC_TO_SUSPEND_END_ANA rw — Number of uSec to suspend end threshold. Represents a time threshold (in micro seconds) from the end of packet when a SuspendEnd interrupt is issued when suspendType==SUSPEND_FD_ANA
  [6:0] MEM_RX_CTRL_USEC_TO_SUSPEND_END_PLL rw — Number of uSec to suspend end threshold. Represents a time threshold (in micro seconds) from the end of packet when a SuspendEnd interrupt is issued when suspendType==SUSPEND_FD_ANA_PLL
0x258 rx_ctrl_status_registers ro reset 0x0
  [29:28] RX_CTRL_SUSPEND_STATE — SUSPEND_IDLE = 2'd0 SUSPEND_REC = 2'd1 SUSPEND = 2'd2
  [27:24] RX_CTRL_PHYB_STATE — PHYB_STATE_IDLE = 4'd0, PHYB_STATE_WAIT_B = 4'd1, PHYB_STATE_B_N_ACTIVE = 4'd2, PHYB_STATE_PENDING_B = 4'd3, PHYB_STATE_ONLY_B = 4'd4, PHYB_STATE_ONLY_N = 4'd5, PHYB_STATE_B_HDR = 4'd6, PHYB_STATE_HDR_PRE_DONE = 4'd7, PHYB_STATE_HDR_PRE_LAST = 4'd8, PHYB_STATE_B_DONE = 4'd9, PHYB_STATE_B_SUSPEND = 4'd10
  [21:16] RX_CTRL_STATE — STATE_IDLE = 6'd0, STATE_START_TD = 6'd1, STATE_SEARCH = 6'd2, STATE_WAIT_BD = 6'd3, STATE_LS_PROCESSING = 6'd4, STATE_FFTP_TIMER = 6'd5, STATE_L_CH_EST = 6'd6, STATE_UNKNOWN1 = 6'd7, STATE_UNKNOWN2 = 6'd8, STATE_UNKNOWN3 = 6'd9, STATE_HT_STF = 6'd10, STATE_HT_LTF = 6'd11, STATE_VHT_STF = 6'd12, STATE_VHT_LTF = 6'd13, STATE_VHT_SIGB = 6'd14, STATE_HE_STF = 6'd15, STATE_HE_LTF = 6'd16, STATE_HE_SIGA2 = 6'd17, STATE_HE_SIGB_OR_SIGA3 = 6'd18, STATE_HE_SIGA4 = 6'd19, STATE_HE_SIGB = 6'd20, STATE_OFDM6_OR_VHT_STF = 6'd21, STATE_DATA1 = 6'd22, STATE_DATA2 = 6'd23, STATE_LAST_SYMBOL = 6'd24, STATE_PE = 6'd25, STATE_UNSUPPORTED1 = 6'd26, STATE_UNSUPPORTED2 = 6'd27, STATE_ABORT = 6'd28, STATE_STOMP = 6'd29, STATE_START_TD_STOMP = 6'd30, STATE_11B = 6'd31, STATE_WAIT_4_11B_TD_EOP = 6'd32, STATE_SUSPEND1 = 6'd33, STATE_SUSPEND2 = 6'd34, STATE_11B_SUSPEND = 6'd35, STATE_HE_MU_UNASSOCIATED1 = 6'd36, STATE_HE_MU_UNASSOCIATED2 = 6'd37
  [15:0] RX_CTRL_SYMB_CNT — RxControl symbol counte
0x25C rx_ctrl_wrcl_register reset 0x0
  [16] RX_CTRL_SM_2_IDLE_WRCL wo — Forces RxbSM to idle state. triggered from FW. Self Clear
  [8] FW_SUSPEND_TRIGGER_EMULATION_WRCL wo — starts rx suspend - triggered from FW. Self Clear
  [0] RX_CTRL_PHYB_TO_IDLE_WRCL wo — Forces Rx11bSM to idle state. triggered from FW. Self Clear
0x260 cca_ed_thr_0 — Energy threshold and Hysthersis for ED/ED-CS - ED (to be used when no packet was detected) and ED-CS (to be used when packet was detected)
  [28:24] MEM_CCA_ED_THR_LOW_CS_UNKNOWN_HYST rw — <5.0u> - Hysteresis for Energy threshold for CS (between Low and Mid), when CS is unknown [dB]
  [23:16] MEM_CCA_ED_THR_LOW_CS_UNKNOWN rw — <8.0s> - Energy threshold for CS (between Low and Mid), when CS is unknown [dBm]
  [12:8] MEM_CCA_ED_THR_HIGH_HYST rw — <5.0u> - Hysteresis for Energy threshold for ED (between Mid and High) [dB]
  [7:0] MEM_CCA_ED_THR_HIGH rw — <8.0s> - Energy threshold for ED (between Mid and High) [dBm]
0x264 cca_ed_thr_1 — Energy threshold and Hysthersis for ED/ED-CS - ED (to be used when no packet was detected) and ED-CS (to be used when packet was detected)
  [28:24] MEM_CCA_ED_THR_LOW_11B_CS_HYST rw — <5.0u> - Hysteresis for Energy threshold for CS (between Low and Mid), when CS is 11B [dB]
  [23:16] MEM_CCA_ED_THR_LOW_11B_CS rw — <8.0s> - Energy threshold for CS (between Low and Mid), when CS is 11B [dBm]
  [12:8] MEM_CCA_ED_THR_LOW_OFDM_CS_HYST rw — <5.0u> - Hysteresis for Energy threshold for CS (between Low and Mid), when CS is OFDM [dB]
  [7:0] MEM_CCA_ED_THR_LOW_OFDM_CS rw — <8.0s> - Energy threshold for CS (between Low and Mid), when CS is OFDM [dBm]
0x268 cca_states_timer_0 — Duration inside FSM states. Moving to next state when timer expired.
  [20:16] MEM_CCA_CS_POST_PACKET_HOLD_TIMER rw — <5.0u> - In CS-Type generation, This is the duration in which the CS-Type is 'held' following TdEop. Note that the CS FSMs may already go on to search for the next packet, while the CS-Type sampled at TdEop is still used (for the duration of this register) [40MHz clocks]
  [7:0] MEM_CCA_OFDM_STATE_UNKNOWN_TIMER rw — <8.0u> - Duration inside OFDM_UNKNOWN state. After this FSM goes into NoOFDM
0x26C cca_states_timer_1 reset 0x8080000 (reset mask 0xFFFFC000) — Duration inside FSM states. Moving to next state when timer expired.
  [13:8] MEM_CCA_11B_STATE_BLANKING_TIMER rw — <6.0u> - In CCA 11B FSM, duration inside ELEVENB_BLANKING state. This is the state after AGC steps. After this, FSM goes back into ELEVENB_UNKNOWN state [40MHz clocks]
  [7:0] MEM_CCA_11B_STATE_UNKNOWN_TIMER rw — <8.0u> - In CCA 11B FSM, duration inside ELEVENB_UNKNOWN state. After this FSM goes into No11B, i.e. into Clear-11B-CS-CCA [40MHz clocks]
0x270 cca_cfg reset 0x0 — CCA module - Control register
  [8] MEM_CCA_USE_STF_EM rw — Enable STF EM latching feature. When false, the running energy estimation is always used. When true, latching of StfPacketEnergy at PD - resetting of this latch.
  [0] FW_CCA_TO_IDLE_WRCL wo — [wrcl] - Dynamic register used to reset CCA module - Used both for 'PhyCCA' and 'QualCCA'
0x274 cca_qual_signal_ext_0 — QualCCA - Signal extension after packet is over
  [23:16] MEM_CCA_SIGNAL_EXTENSION_ONE_SYMBOL_LEGACY rw — <8.0u> - [Default: 80 (2usec)] The duration of signal extension (holding QualCca high after TdEop) in legacy packets with 1 data symbol. In this case the TdEop comes 4uSec later than the last symbol, so special care is taken to compensate via lowering the signal-extension.
  [15:8] MEM_CCA_SIGNAL_EXTENSION_OFDM rw — <8.0u> - The duration of signal extension (holding QualCca high after packet is over) in OFDM packets. [40MHz clock cycles]
  [7:0] MEM_CCA_SIGNAL_EXTENSION_11B rw — <8.0u> - The duration of signal extension (holding QualCca high after packet is over) in 11B packets. [40MHz clock cycles]
0x278 cca_qual_signal_ext_1 reset 0x0 — QualCCA - Signal extension after packet is over
  [8] MEM_CCA_SIGNAL_EXTENSION_FW_OVRD rw — When true, Signal-extension period uses the value set in SignalExtensionFwVal
  [7:0] MEM_CCA_SIGNAL_EXTENSION_FW_VAL rw — <8.0u> - The duration of signal extension (holding QualCca high after packet is over), used when SignalExtensionFwOvrd is true.
0x27C cca_qual_4usec_align reset 0x2800 (reset mask 0xFFFFFC00) — QualCCA - Determine whether QualCCA is aligned to 4uSec or not
  [9] MEM_CCA_ALLOW_4USEC_ALIGNMENT_FW_OVRD rw — When true, Allow4UsecAlignmentFwVal is used to enable/disable the 4uSec alignment of the QualCca desertion
  [8] MEM_CCA_ALLOW_4USEC_ALIGNMENT_FW_VAL rw — When Allow4UsecAlignmentFwOvrd is true, this register is used to enable the 4uSec alignment. When true desertion of QualCca will be aligned with the 4uSec boundary integer multiple.
  [4] MEM_CCA_ALIGN_TO_4USEC_IN_OTHER rw — When true desertion of QualCca in packets which are not mentioned above, will be aligned with the 4uSec boundary integer multiple.
  [3] MEM_CCA_ALIGN_TO_4USEC_IN_HE_WITH_SIG_A_ERR_OR_RESERVED rw — When true desertion of QualCca in HE packets with HE-SIG-A CRC error or with HE-SIG-A reserved field, will be aligned with the 4uSec boundary integer multiple. (since RxTime is calculated from the L-SIG in this case).
  [2] MEM_CCA_ALIGN_TO_4USEC_IN_HE_NO_SIG_A_ERR rw — When false desertion of QualCca in HE packets with no HE-SIG-A CRC error will NOT be aligned with the 4uSec boundary integer multiple.
  [1] MEM_CCA_ALIGN_TO_4USEC_IN_HT_AND_VHT rw — When true desertion of QualCca in HT and VHT packets will be aligned with the 4uSec boundary integer multiple. This is required by protocol (to align the ack or the slots following a short-guard-interval packet between HT/VHT and legacy devices).
  [0] MEM_CCA_ALIGN_TO_4USEC_IN_11B rw — When true desertion of QualCca in 11b packets will be aligned with the 4uSec boundary integer multiple
0x280 cca_qual_4usec_corr reset 0x294 — QualCCA - Correction for alignment of 4uSec
  [4:0] MEM_CCA_ANTENNA_TO_TD_RAM_PROPAGATION_TIME rw — <5.0u> - Propagation time from antenna to TdRam. This is used to fine-tune the location of the 4uSec boundary in time, so that it is aligned with the antenna (and not with the TdRam as the corrected BD is) [40MHz samples].
0x284 cca_qual_stat ro reset 0x0 — QualCCA - Status of 4uSec alignment
  [8] PACKET_ALIGNED_TO_4USEC_BOUNDRY — [RO] - This is automatically latched at TdEop, marking whether the packet s QualCca desertion was forcefully aligned to the 4uSec boundary.
  [7:0] TD_EOP_TO_4USEC_BOUNDRY — <8.0u> - Read-only register. This is automatically latched at TdEop, measuring the time between TdEop and the coming 4uSec boundary.
0x288 cca_ovrd reset 0x0 — Override Qual/Phy CCA output controls
  [16] QUAL_CCA_FW_LATCH_TO_BUSY_WRCL wo — [wrcl] - A pulse in this register will set the QualCca to busy till packet end
  [9] MEM_CCA_QUAL_CCA_FW_OVRD rw — When true, QualCca is controlled by QualCcaFwVal
  [8] MEM_CCA_QUAL_CCA_FW_VAL rw — When QualCcaFwOvrd is true, this register sets the QualCca
  [1] MEM_CCA_PHY_CCA_FW_OVRD rw — When true, PhyCca is controlled by PhyCcaFwVal
  [0] MEM_CCA_PHY_CCA_FW_VAL rw — When PhyCcaFwOvrd is true, this register sets the PhyCca
0x28C cca_snap_state_stat reset 0x0 — Snapshot of CCA Module status and states
  [24] FW_SNAP_CCA_STATE_WRCL wo — [wrcl] - Snapshots CCA states and signals into CsTypeSnap, EdTypeSnap, OfdmCsFsmStateSnap, ElevenBCsFsmStateSnap, EdFsmStateSnap, PhyCcaInternalSnap and QualCcaInternalSnap registers.
  [23:16] STF_PACKET_ENERGY_SNAP ro — 'Snapshot' by FwSnapCcaState. Energy measurement coming from RxMeters Stomp path (typically 800nSec MA). Used only to latch the OFDM packet energy estimation during STF
  [15] QUAL_CCA_INTERNAL_SNAP ro — Snapshot by FwSnapCcaState.
  [14] PHY_CCA_INTERNAL_SNAP ro — Snapshot by FwSnapCcaState.
  [13:11] ELEVENB_CS_FSM_STATE_SNAP ro — Snapshot by FwSnapCcaState. 0-STATE_IDLE ; 1-STATE_UNKNOWN ; 2-STATE_BLANKING ; 3-NO_11B ; 4-PRE_11B_CS ; 5-11B_CS ; 6-11B_POST_PACKET
  [10:8] OFDM_CS_FSM_STATE_SNAP ro — Snapshot by FwSnapCcaState. 0-STATE_IDLE ; 1-STATE_UNKNOWN ; 2-STATE_BLANKING ; 3-NO_OFDM ; 4-PRE_OFDM_CS ; 5-OFDM_CS ; 6-OFDM_POST_PACKET
  [7] STF_EM_FSM_STATE_SNAP ro — 'Snapshot' by FwSnapCcaState. StfEmLatchingFsmState: 0-USING_RUNNING_EM ; 1-USING_STF_EM ;
  [6:4] ED_FSM_STATE_SNAP ro — Snapshot by FwSnapCcaState. 0-IDLE ; 1-IDLE ; 2-HIGH ; 3-LOW ; 4-MID
  [3:2] ED_TYPE_SNAP ro — Snapshot by FwSnapCcaState. 0-ED_TYPE_LOW ; 1-ED_TYPE_MID ; 2-ED_TYPE_HIGH
  [1:0] CS_TYPE_SNAP ro — Snapshot by FwSnapCcaState. 0-CS_TYPE_IDLE ; 1-CS_TYPE_OFDM ; 2-CS_TYPE_11_B ; 3-CS_TYPE_BUSY
